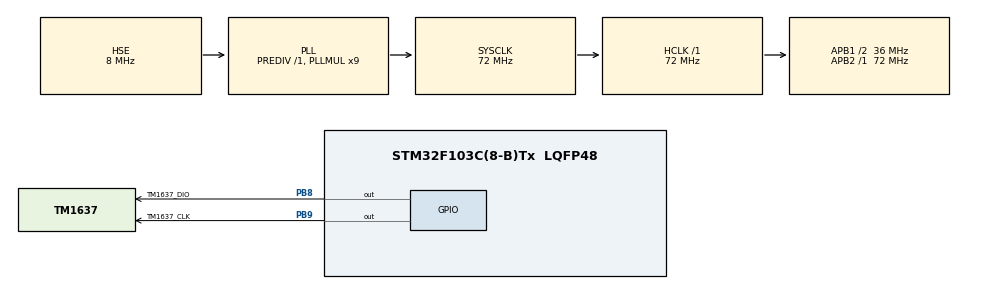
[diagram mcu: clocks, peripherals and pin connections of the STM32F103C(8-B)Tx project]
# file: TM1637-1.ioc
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Mcu.Family=STM32F1
RCC.PLLSourceVirtual=RCC_PLLSOURCE_HSE
PD1-OSC_OUT.Mode=HSE-External-Oscillator
PB9.GPIO_Label=TM1637_CLK
PB8.GPIO_PuPd=GPIO_NOPULL
PB9.GPIO_ModeDefaultOutputPP=GPIO_MODE_OUTPUT_OD
NVIC.TIM1_UP_IRQn=true\:0\:0\:false\:false\:true\:false\:true
PD0-OSC_IN.Signal=RCC_OSC_IN
RCC.APB1CLKDivider=RCC_HCLK_DIV2
RCC.SYSCLKSource=RCC_SYSCLKSOURCE_PLLCLK
ProjectManager.StackSize=0x400
PD1-OSC_OUT.Signal=RCC_OSC_OUT
PA13.Signal=SYS_JTMS-SWDIO
PB8.GPIO_Label=TM1637_DIO
ProjectManager.TargetToolchain=STM32CubeIDE
RCC.HCLKFreq_Value=72000000
RCC.APB2TimFreq_Value=72000000
RCC.USBFreq_Value=72000000
RCC.AHBFreq_Value=72000000
PD0-OSC_IN.Mode=HSE-External-Oscillator
board=custom
RCC.PLLMUL=RCC_PLL_MUL9
RCC.APB2Freq_Value=72000000
PA14.Mode=Serial_Wire
VP_SYS_VS_tim1.Mode=TIM1
PB8.PinState=GPIO_PIN_SET
PA13.Mode=Serial_Wire
Mcu.Name=STM32F103C(8-B)Tx
RCC.SYSCLKFreq_VALUE=72000000
Mcu.Package=LQFP48
PB9.Signal=GPIO_Output
NVIC.TimeBase=TIM1_UP_IRQn
PB9.PinState=GPIO_PIN_SET
NVIC.TimeBaseIP=TIM1
PA14.Signal=SYS_JTCK-SWCLK
ProjectManager.HeapSize=0x200
PB8.GPIO_ModeDefaultOutputPP=GPIO_MODE_OUTPUT_OD
NVIC.PriorityGroup=NVIC_PRIORITYGROUP_4
PB9.GPIO_Speed=GPIO_SPEED_FREQ_MEDIUM
RCC.APB1TimFreq_Value=72000000
PB8.Signal=GPIO_Output
RCC.APB1Freq_Value=36000000
PB8.GPIO_Speed=GPIO_SPEED_FREQ_MEDIUM

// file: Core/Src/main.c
/* USER CODE BEGIN Header */
/**
  ******************************************************************************
  * @file           : main.c
  * @brief          : Main program body
  ******************************************************************************
  * @attention
  *
  * <h2><center>&copy; Copyright (c) 2024 STMicroelectronics.
  * All rights reserved.</center></h2>
  *
  * This software component is licensed by ST under BSD 3-Clause license,
  * the "License"; You may not use this file except in compliance with the
  * License. You may obtain a copy of the License at:
  *                        opensource.org/licenses/BSD-3-Clause
  *
  ******************************************************************************
  */
/* USER CODE END Header */
#include "main.h"

/* USER CODE BEGIN Includes */
#include "tm1637_lib.h"
/* USER CODE END Includes */

int numero = 3;

void SystemClock_Config(void);
static void MX_GPIO_Init(void);

int main(void)
{

  /* MCU Configuration--------------------------------------------------------*/

  /* Reset of all peripherals, Initializes the Flash interface and the Systick. */
  HAL_Init();

  /* Configure the system clock */
  SystemClock_Config();

  /* Initialize all configured peripherals */
  MX_GPIO_Init();
  /* USER CODE BEGIN 2 */
  tm1637_SetBrightness(3);//Set max brightness
  tm1637_DisplayUpdate(0,0,0,0);//Clear display (all segments off)

  /* USER CODE END 2 */

  /* Infinite loop */
  while (1)
  {
	  //tm1637_DisplayUpdate(0,0,0,tm1637_NumberToSegments(numero));
	  HAL_Delay(50);
	  tm1637_ShowNumber(numero);
	  //HAL_Delay(50);
  }
}

void SystemClock_Config(void)
{
  RCC_OscInitTypeDef RCC_OscInitStruct = {0};
  RCC_ClkInitTypeDef RCC_ClkInitStruct = {0};

  /** Initializes the RCC Oscillators according to the specified parameters
  * in the RCC_OscInitTypeDef structure.
  */
  RCC_OscInitStruct.OscillatorType = RCC_OSCILLATORTYPE_HSE;
  RCC_OscInitStruct.HSEState = RCC_HSE_ON;
  RCC_OscInitStruct.HSEPredivValue = RCC_HSE_PREDIV_DIV1;
  RCC_OscInitStruct.HSIState = RCC_HSI_ON;
  RCC_OscInitStruct.PLL.PLLState = RCC_PLL_ON;
  RCC_OscInitStruct.PLL.PLLSource = RCC_PLLSOURCE_HSE;
  RCC_OscInitStruct.PLL.PLLMUL = RCC_PLL_MUL9;
  if (HAL_RCC_OscConfig(&RCC_OscInitStruct) != HAL_OK)
  {
    Error_Handler();
  }
  /** Initializes the CPU, AHB and APB buses clocks
  */
  RCC_ClkInitStruct.ClockType = RCC_CLOCKTYPE_HCLK|RCC_CLOCKTYPE_SYSCLK
                              |RCC_CLOCKTYPE_PCLK1|RCC_CLOCKTYPE_PCLK2;
  RCC_ClkInitStruct.SYSCLKSource = RCC_SYSCLKSOURCE_PLLCLK;
  RCC_ClkInitStruct.AHBCLKDivider = RCC_SYSCLK_DIV1;
  RCC_ClkInitStruct.APB1CLKDivider = RCC_HCLK_DIV2;
  RCC_ClkInitStruct.APB2CLKDivider = RCC_HCLK_DIV1;

  if (HAL_RCC_ClockConfig(&RCC_ClkInitStruct, FLASH_LATENCY_2) != HAL_OK)
  {
    Error_Handler();
  }
}

static void MX_GPIO_Init(void)
{
  GPIO_InitTypeDef GPIO_InitStruct = {0};

  /* GPIO Ports Clock Enable */
  __HAL_RCC_GPIOD_CLK_ENABLE();
  __HAL_RCC_GPIOA_CLK_ENABLE();
  __HAL_RCC_GPIOB_CLK_ENABLE();

  /*Configure GPIO pin Output Level */
  HAL_GPIO_WritePin(GPIOB, TM1637_DIO_Pin|TM1637_CLK_Pin, GPIO_PIN_SET);

  /*Configure GPIO pins : TM1637_DIO_Pin TM1637_CLK_Pin */
  GPIO_InitStruct.Pin = TM1637_DIO_Pin|TM1637_CLK_Pin;
  GPIO_InitStruct.Mode = GPIO_MODE_OUTPUT_OD;
  GPIO_InitStruct.Pull = GPIO_NOPULL;
  GPIO_InitStruct.Speed = GPIO_SPEED_FREQ_MEDIUM;
  HAL_GPIO_Init(GPIOB, &GPIO_InitStruct);

}

 /**
  * @brief  Period elapsed callback in non blocking mode
  * @note   This function is called  when TIM1 interrupt took place, inside
  * HAL_TIM_IRQHandler(). It makes a direct call to HAL_IncTick() to increment
  * a global variable "uwTick" used as application time base.
  * @param  htim : TIM handle
  * @retval None
  */
void HAL_TIM_PeriodElapsedCallback(TIM_HandleTypeDef *htim)
{
  if (htim->Instance == TIM1) {
    HAL_IncTick();
  }
}

void Error_Handler(void)
{
  __disable_irq();
  while (1)
  {
  }
}

/************************ (C) COPYRIGHT STMicroelectronics *****END OF FILE****/
